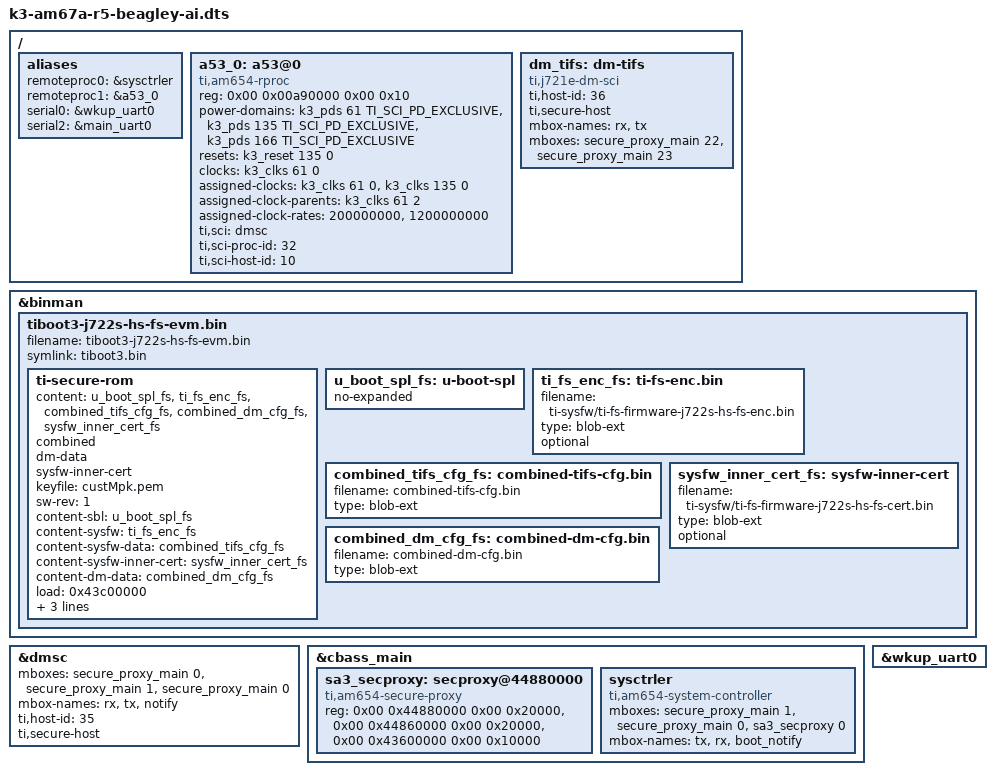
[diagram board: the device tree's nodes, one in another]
// SPDX-License-Identifier: GPL-2.0
/*
 * https://beagley-ai.org/
 *
 * Copyright (C) 2024 Texas Instruments Incorporated - https://www.ti.com/
 * Copyright (C) 2024 Robert Nelson, BeagleBoard.org Foundation
 */

#include "k3-am67a-beagley-ai.dts"
#include "k3-am67a-beagley-ai-u-boot.dtsi"
#include "k3-am67a-beagley-ddr-lp4.dtsi"
#include "k3-am62a-ddr.dtsi"

/ {
	aliases {
		remoteproc0 = &sysctrler;
		remoteproc1 = &a53_0;
		serial0 = &wkup_uart0;
		serial2 = &main_uart0;
	};

	a53_0: a53@0 {
		compatible = "ti,am654-rproc";
		reg = <0x00 0x00a90000 0x00 0x10>;
		power-domains = <&k3_pds 61 TI_SCI_PD_EXCLUSIVE>,
			<&k3_pds 135 TI_SCI_PD_EXCLUSIVE>,
			<&k3_pds 166 TI_SCI_PD_EXCLUSIVE>;
		resets = <&k3_reset 135 0>;
		clocks = <&k3_clks 61 0>;
		assigned-clocks = <&k3_clks 61 0>, <&k3_clks 135 0>;
		assigned-clock-parents = <&k3_clks 61 2>;
		assigned-clock-rates = <200000000>, <1200000000>;
		ti,sci = <&dmsc>;
		ti,sci-proc-id = <32>;
		ti,sci-host-id = <10>;
		bootph-all;
	};

	dm_tifs: dm-tifs {
		compatible = "ti,j721e-dm-sci";
		ti,host-id = <36>;
		ti,secure-host;
		mbox-names = "rx", "tx";
		mboxes= <&secure_proxy_main 22>,
			<&secure_proxy_main 23>;
		bootph-all;
	};
};

&binman {
        tiboot3-j722s-hs-fs-evm.bin {
                filename = "tiboot3-j722s-hs-fs-evm.bin";
                symlink = "tiboot3.bin";
                ti-secure-rom {
                        content = <&u_boot_spl_fs>, <&ti_fs_enc_fs>, <&combined_tifs_cfg_fs>,
                                <&combined_dm_cfg_fs>, <&sysfw_inner_cert_fs>;
                        combined;
                        dm-data;
                        sysfw-inner-cert;
                        keyfile = "custMpk.pem";
                        sw-rev = <1>;
                        content-sbl = <&u_boot_spl_fs>;
                        content-sysfw = <&ti_fs_enc_fs>;
                        content-sysfw-data = <&combined_tifs_cfg_fs>;
                        content-sysfw-inner-cert = <&sysfw_inner_cert_fs>;
                        content-dm-data = <&combined_dm_cfg_fs>;
                        load = <0x43c00000>;
                        load-sysfw = <0x40000>;
                        load-sysfw-data = <0x67000>;
                        load-dm-data = <0x43c7a800>;
                };
                u_boot_spl_fs: u-boot-spl {
                        no-expanded;
                };
                ti_fs_enc_fs: ti-fs-enc.bin {
                        filename = "ti-sysfw/ti-fs-firmware-j722s-hs-fs-enc.bin";
                        type = "blob-ext";
                        optional;
                };
                combined_tifs_cfg_fs: combined-tifs-cfg.bin {
                        filename = "combined-tifs-cfg.bin";
                        type = "blob-ext";
                };
                sysfw_inner_cert_fs: sysfw-inner-cert {
                        filename = "ti-sysfw/ti-fs-firmware-j722s-hs-fs-cert.bin";
                        type = "blob-ext";
                        optional;
                };
                combined_dm_cfg_fs: combined-dm-cfg.bin {
                        filename = "combined-dm-cfg.bin";
                        type = "blob-ext";
                };
        };
};

&dmsc {
	mboxes= <&secure_proxy_main 0>,
		<&secure_proxy_main 1>,
		<&secure_proxy_main 0>;
	mbox-names = "rx", "tx", "notify";
	ti,host-id = <35>;
	ti,secure-host;
};

&cbass_main {
	sa3_secproxy: secproxy@44880000 {
		compatible = "ti,am654-secure-proxy";
		#mbox-cells = <1>;
		reg = <0x00 0x44880000 0x00 0x20000>,
		      <0x00 0x44860000 0x00 0x20000>,
		      <0x00 0x43600000 0x00 0x10000>;
		reg-names = "rt", "scfg", "target_data";
		bootph-all;
	};

	sysctrler: sysctrler {
		compatible = "ti,am654-system-controller";
		mboxes= <&secure_proxy_main 1>,
			<&secure_proxy_main 0>,
			<&sa3_secproxy 0>;
		mbox-names = "tx", "rx", "boot_notify";
		bootph-all;
	};
};

/* WKUP UART0 is used for DM firmware logs */
&wkup_uart0 {
	status = "okay";
};
